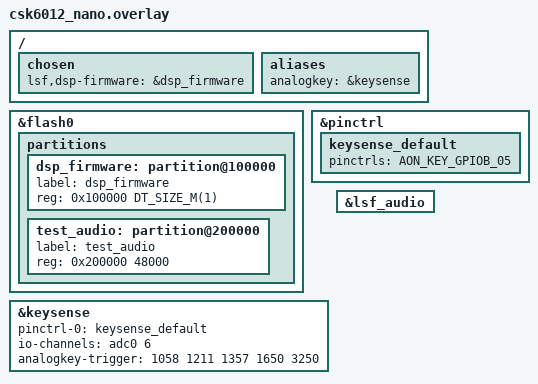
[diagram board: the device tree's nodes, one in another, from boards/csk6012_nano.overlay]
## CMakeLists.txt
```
# Copyright (c) 2023 LISTENAI
# SPDX-License-Identifier: Apache-2.0

cmake_minimum_required(VERSION 3.20.0)

find_package(Zephyr REQUIRED HINTS $ENV{ZEPHYR_BASE})
project(audio_recorder_multichannel)

target_sources(app PRIVATE src/main.c)
target_sources(app PRIVATE src/play_thread.c)
target_sources(app PRIVATE src/record_thread.c)
```

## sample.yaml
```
sample:
  name: audio_recorder_multichannel
tests:
  sample.audio_recorder_multichannel:
    tags: audio
```

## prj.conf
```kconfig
CONFIG_HEAP_MEM_POOL_SIZE=204800

CONFIG_CSK_HEAP=y
CONFIG_CSK_HEAP_MEM_POOL_SIZE=40960

CONFIG_CSK6_FLASH_STALL_SECOND_CORE=n

CONFIG_GPIO=y

CONFIG_ADC=y

CONFIG_KSCAN=y
CONFIG_KSCAN_CSK6=y

CONFIG_LOG=y
```

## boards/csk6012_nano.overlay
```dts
/*
 * Copyright(c) 2023 LISTENAI
 * SPDX-License-Identifier: Apache-2.0
 */

#include <lsf/lsf.dtsi>

/ {
	chosen {
		lsf,dsp-firmware = &dsp_firmware;
	};

	aliases {
		analogkey = &keysense;
	};
};

&flash0 {
	partitions {
		dsp_firmware: partition@100000 {
			label = "dsp_firmware";
			reg = <0x100000 DT_SIZE_M(1)>;
		};

		test_audio: partition@200000 {
			label = "test_audio";
			reg = <0x200000 48000>;
		};
	};
};

&pinctrl {
	keysense_default: keysense_default {
		pinctrls = <AON_KEY_GPIOB_05>;
	};
};

&keysense {
	status = "okay";
	pinctrl-0 = <&keysense_default>;
	pinctrl-names = "default";
	io-channels = <&adc0 6>;
	analogkey-trigger = <
		1058 /* K4 */
		1211 /* K3 */
		1357 /* K2 */
		1650 /* K1 */
		3250 /* SW2 */
	>;
};

&lsf_audio {
	status = "okay";
};
```

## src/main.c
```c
/*
 * Copyright(c) 2023 LISTENAI
 * SPDX-License-Identifier: Apache-2.0
 */

#include <assert.h>

#include <zephyr/kernel.h>
#include <zephyr/device.h>
#include <zephyr/drivers/kscan.h>

#include <zephyr/logging/log.h>
LOG_MODULE_REGISTER(main);

#include "AudioSystem.h"
#include "AudioTrack.h"
#include "AudioRecord.h"

#include "play_thread.h"
#include "record_thread.h"

enum csk_adc_key_t {
	KEY_K4,
	KEY_K3,
	KEY_K2,
	KEY_K1,
	KEY_SW2,
};

static const struct device *kscan = DEVICE_DT_GET(DT_ALIAS(analogkey));

AudioTrack g_track;
AudioRecord g_record;

static void kscan_callback(const struct device *dev, uint32_t row, uint32_t column, bool pressed)
{
	if (!pressed) {
		return;
	}

	LOG_INF("Key %d pressed at %" PRIu32, row, k_cycle_get_32());

	switch (row) {
	case KEY_SW2:
		record_thread_start();
		break;
	case KEY_K1:
		play_thread_start();
		break;
	case KEY_K2:
		play_thread_stop();
		break;
	case KEY_K3:
		play_thread_mute();
		break;
	case KEY_K4:
		play_thread_unmute();
		break;
	}
}

void main(void)
{
	int ret;

	LOG_INF("Hello World! %s", CONFIG_BOARD);

	String8 param;
	String8_ctor_char(&param, "ADC_PDM_GAIN_A_LEFT=6;"
				  "ADC_PDM_GAIN_D_LEFT=20;"
				  "ADC_PDM_GAIN_A_RIGHT=6;"
				  "ADC_PDM_GAIN_D_RIGHT=20");
	ret = AudioSystem_setParameters(0, &param);
	String8_dtor(&param);
	assert(0 == ret);

	ret = AudioTrack_ctor(&g_track, 16000, PCM_16_BIT, CHANNEL_OUT_MONO, 0, NULL);
	assert(ret == 0);

	ret = AudioRecord_ctor(&g_record, 0, 16000, PCM_16_BIT,
			       CHANNEL_IN_STEREO | CHANNEL_IN_AUX | CHANNEL_IN_ECHO, 0, NULL);
	assert(ret == 0);

	kscan_config(kscan, kscan_callback);
}
```

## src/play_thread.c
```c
/*
 * Copyright(c) 2023 LISTENAI
 * SPDX-License-Identifier: Apache-2.0
 */

#include <assert.h>

#include <zephyr/kernel.h>
#include <zephyr/device.h>
#include <zephyr/storage/flash_map.h>

#include <zephyr/logging/log.h>
LOG_MODULE_REGISTER(play_thread);

#include "AudioSystem.h"
#include "AudioTrack.h"

#define FLASH_ADDR      (DT_REG_ADDR(DT_CHOSEN(zephyr_flash)))
#define TEST_AUDIO_ADDR (FLASH_ADDR + FLASH_AREA_OFFSET(test_audio))
#define TEST_AUDIO_SIZE (FLASH_AREA_SIZE(test_audio))

extern AudioTrack g_track;

static struct k_sem s_sem_run;
static volatile bool s_busy;

#define CHANNEL_CNT (1)

extern void play_thread(void *p1, void *p2, void *p3)
{
	int ret;
	ssize_t wrote;

	ret = k_sem_init(&s_sem_run, 0, 1);
	assert(ret == 0);

	while (1) {
		LOG_INF("K1=PLAY, K2=STOP, K3=MUTE, K4=UNMUTE");
		k_sem_take(&s_sem_run, K_FOREVER);
		s_busy = true;

		AudioTrack_start(&g_track);
		LOG_INF("Start playing...");

		wrote = AudioTrack_write(&g_track, (const void *)TEST_AUDIO_ADDR, TEST_AUDIO_SIZE);
		LOG_INF("Actual wrote %d of %d bytes", wrote, TEST_AUDIO_SIZE);

		AudioTrack_stop(&g_track);

		s_busy = false;
	}
}

#define PLAY_THREAD_STACK_SIZE (16 * 1024)
#define PLAY_THREAD_PRIORITY   (5)

K_THREAD_DEFINE(play_thread_tid, PLAY_THREAD_STACK_SIZE, play_thread, NULL, NULL, NULL,
		PLAY_THREAD_PRIORITY, 0, 0);

void play_thread_start(void)
{
	if (!s_busy) {
		LOG_INF("Start");
		k_sem_give(&s_sem_run);
	}
}

void play_thread_stop(void)
{
	LOG_INF("Stop");
	AudioTrack_stop(&g_track);
}

void play_thread_mute(void)
{
	LOG_INF("Mute");
	AudioTrack_mute(&g_track, true);
}

void play_thread_unmute(void)
{
	LOG_INF("Unmute");
	AudioTrack_mute(&g_track, false);
}

#define SAMPLE_PER_MS (16)
#define INSPECT_MS    (5000)

__attribute__((section(".psram_section"))) static int16_t inspect_buf[SAMPLE_PER_MS * INSPECT_MS];

void play_thread_inspect(const void *buffer, size_t bytes, uint32_t channels)
{
	size_t frames = bytes / sizeof(int16_t) / channels;
	if (frames > SAMPLE_PER_MS * INSPECT_MS) {
		frames = SAMPLE_PER_MS * INSPECT_MS;
	}

	LOG_INF("Inspecting %d frames", frames);

	s_busy = true;

	for (int i = 0; i < channels; i++) {
		k_msleep(500);
		LOG_INF("Inspect channel %d", i);

		for (int j = 0; j < frames; j++) {
			inspect_buf[j] = ((int16_t *)buffer)[j * channels + i];
		}

		LOG_HEXDUMP_INF(inspect_buf, MIN(64, frames * sizeof(int16_t)), "Inspect data");

		AudioTrack_start(&g_track);

		AudioTrack_write(&g_track, inspect_buf, frames * sizeof(int16_t));

		AudioTrack_stop(&g_track);
	}

	LOG_INF("Inspect done");

	s_busy = false;
}
```

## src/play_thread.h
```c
#pragma once

#include <stdint.h>

void play_thread_start(void);
void play_thread_stop(void);
void play_thread_mute(void);
void play_thread_unmute(void);

void play_thread_inspect(const void *buffer, size_t bytes, uint32_t channels);
```

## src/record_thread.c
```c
/*
 * Copyright(c) 2023 LISTENAI
 * SPDX-License-Identifier: Apache-2.0
 */

#include <assert.h>

#include <zephyr/kernel.h>
#include <zephyr/device.h>
#include <zephyr/drivers/gpio.h>

#include <zephyr/logging/log.h>
LOG_MODULE_REGISTER(record_thread);

#include "AudioSystem.h"
#include "AudioRecord.h"

#include "play_thread.h"

static const struct gpio_dt_spec led = GPIO_DT_SPEC_GET(DT_ALIAS(led0), gpios);

extern AudioRecord g_record;

static struct k_sem s_sem_run;
static volatile bool s_busy;

#define CHANNEL_CNT   (6)
#define SAMPLE_PER_MS (16)
#define DURATION_MS   (5000)

__attribute__((section(
	".psram_section"))) static int16_t record_buf[SAMPLE_PER_MS * DURATION_MS * CHANNEL_CNT];

static void record_thread(void *p1, void *p2, void *p3)
{
	int ret;
	ssize_t read;
	uint32_t start_time, end_time;

	ret = k_sem_init(&s_sem_run, 0, 1);
	assert(ret == 0);

	ret = gpio_pin_configure_dt(&led, GPIO_OUTPUT_INACTIVE);
	assert(0 == ret);

	while (1) {
		LOG_INF("Press SW2 to record");
		k_sem_take(&s_sem_run, K_FOREVER);
		s_busy = true;

		gpio_pin_set_dt(&led, 1);
		LOG_INF("Records 5 seconds...");

		AudioRecord_start(&g_record);

		start_time = k_uptime_get_32();
		read = AudioRecord_read(&g_record, record_buf, sizeof(record_buf));
		end_time = k_uptime_get_32();

		AudioRecord_stop(&g_record);

		gpio_pin_set_dt(&led, 0);
		LOG_INF("Actual read %d of %d bytes in %d ms", read, sizeof(record_buf),
			end_time - start_time);

		LOG_HEXDUMP_INF(record_buf, MIN(64, read), "Recorded data");

		play_thread_inspect(record_buf, read, CHANNEL_CNT);

		s_busy = false;
	}
}

#define RECORD_THREAD_STACK_SIZE (8 * 1024)
#define RECORD_THREAD_PRIORITY   (5)

K_THREAD_DEFINE(record_thread_tid, RECORD_THREAD_STACK_SIZE, record_thread, NULL, NULL, NULL,
		RECORD_THREAD_PRIORITY, 0, 0);

void record_thread_start(void)
{
	if (!s_busy) {
		k_sem_give(&s_sem_run);
	}
}
```

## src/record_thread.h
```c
#pragma once

void record_thread_start(void);
```
